# S32M24x register map
Vendor: NXP Semiconductors; File version: 1.5
CPU: CM4 r0p1, little endian, MPU, FPU, VTOR, 4 interrupt priority bits
Registers are 32-bit, read-write, reset 0x0 unless marked. A register's access mark holds for its fields unless they carry their own. Offsets are from the block's base; [hi:lo] are bit positions; {n}, {i} and the like mark numbered series; 'fields as' and 'values as' point back to an identical list.

## CRC
Base 0x40032000
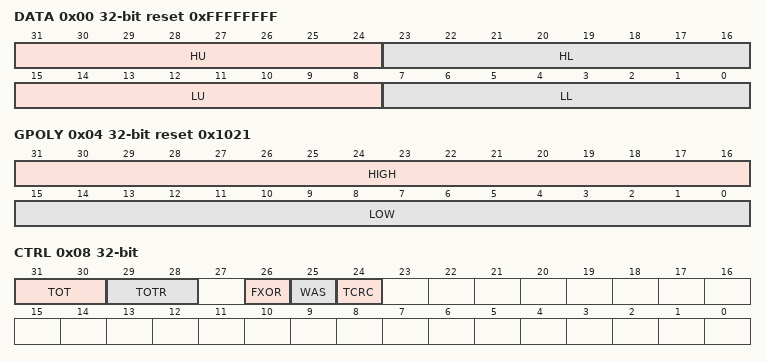
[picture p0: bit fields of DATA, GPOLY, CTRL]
0x00 DATA reset 0xFFFFFFFF — CRC DATA register
  [31:24] HU — CRC High Upper Byte
  [23:16] HL — CRC High Lower Byte
  [15:8] LU — CRC Low Upper Byte
  [7:0] LL — CRC Low Lower Byte
0x04 GPOLY reset 0x1021 — CRC Polynomial register
  [31:16] HIGH — High Polynominal Half-word
  [15:0] LOW — Low Polynominal Half-word
0x08 CTRL — CRC Control register
  [31:30] TOT — Type Of Transpose For Writes
    0=No transposition; 1=Bits in bytes are transposed; bytes are not transposed; 2=Both bits in bytes and bytes are transposed; 3=Only bytes are transposed; no bits in a byte are transposed
  [29:28] TOTR — Type Of Transpose For Read
    values as TOT
  [26] FXOR — Complement Read Of CRC DATA register
    0=No XOR on reading; 1=Invert or complement the read value of the CRC DATA register
  [25] WAS — Write CRC DATA register As Seed
    0=Writes to the CRC DATA register are data values; 1=Writes to the CRC DATA register are seed values
  [24] TCRC
    0=16-bit CRC protocol; 1=32-bit CRC protocol

## LPTMR0 — LPTMR
Base 0x40040000
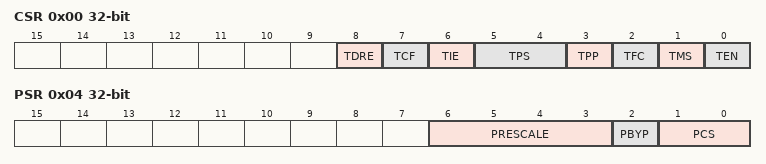
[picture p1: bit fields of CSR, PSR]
0x00 CSR — Low Power Timer Control Status Register
  [8] TDRE — Timer DMA Request Enable
    0=Timer DMA Request disabled; 1=Timer DMA Request enabled
  [7] TCF write-1-clears — Timer Compare Flag
    0=The value of CNR is not equal to CMR and increments; 1=The value of CNR is equal to CMR and increments
  [6] TIE — Timer Interrupt Enable
    0=Timer interrupt disabled; 1=Timer interrupt enabled
  [5:4] TPS — Timer Pin Select
    {v}=Pulse counter input {v} is selected (v=0..3)
  [3] TPP — Timer Pin Polarity
    0=Pulse Counter input source is active-high, and the CNR increments on the rising-edge; 1=Pulse Counter input source is active-low, and the CNR increments on the falling-edge
  [2] TFC — Timer Free-Running Counter
    0=CNR is reset whenever TCF is set; 1=CNR is reset on overflow
  [1] TMS — Timer Mode Select
    0=Time Counter mode; 1=Pulse Counter mode
  [0] TEN — Timer Enable
    0=LPTMR is disabled and internal logic is reset; 1=LPTMR is enabled
0x04 PSR — Low Power Timer Prescale Register
  [6:3] PRESCALE — Prescale Value
    0=Prescaler divides the prescaler clock by 2; glitch filter does not support this configuration; 1=Prescaler divides the prescaler clock by 4; glitch filter recognizes change on input pin after 2 rising clock edges; 2=Prescaler divides the prescaler clock by 8; glitch filter recognizes change on input pin after 4 rising clock edges; 3=Prescaler divides the prescaler clock by 16; glitch filter recognizes change on input pin after 8 rising clock edges; 4=Prescaler divides the prescaler clock by 32; glitch filter recognizes change on input pin after 16 rising clock edges; 5=Prescaler divides the prescaler clock by 64; glitch filter recognizes change on input pin after 32 rising clock edges; 6=Prescaler divides the prescaler clock by 128; glitch filter recognizes change on input pin after 64 rising clock edges; 7=Prescaler divides the prescaler clock by 256; glitch filter recognizes change on input pin after 128 rising clock edges; 8=Prescaler divides the prescaler clock by 512; glitch filter recognizes change on input pin after 256 rising clock edges; 9=Prescaler divides the prescaler clock by 1024; glitch filter recognizes change on input pin after 512 rising clock edges; 10=Prescaler divides the prescaler clock by 2048; glitch filter recognizes change on input pin after 1024 rising clock edges; 11=Prescaler divides the prescaler clock by 4096; glitch filter recognizes change on input pin after 2048 rising clock edges; 12=Prescaler divides the prescaler clock by 8192; glitch filter recognizes change on input pin after 4096 rising clock edges; 13=Prescaler divides the prescaler clock by 16,384; glitch filter recognizes change on input pin after 8192 rising clock edges; 14=Prescaler divides the prescaler clock by 32,768; glitch filter recognizes change on input pin after 16,384 rising clock edges; 15=Prescaler divides the prescaler clock by 65,536; glitch filter recognizes change on input pin after 32,768 rising clock edges
  [2] PBYP — Prescaler Bypass
    0=Prescaler/glitch filter is enabled; 1=Prescaler/glitch filter is bypassed
  [1:0] PCS — Prescaler Clock Select
    {v}=Prescaler/glitch filter clock {v} selected (v=0..3)
0x08 CMR — Low Power Timer Compare Register
  [15:0] COMPARE — Compare Value
0x0C CNR — Low Power Timer Counter Register
  [15:0] COUNTER — Counter Value
